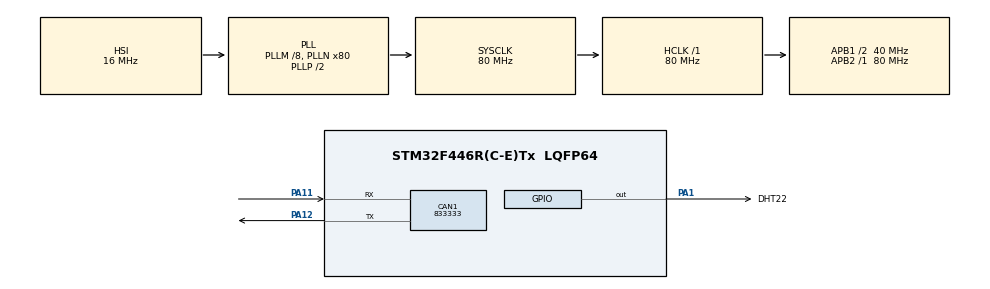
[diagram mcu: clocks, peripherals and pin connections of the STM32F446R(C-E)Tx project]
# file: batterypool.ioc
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CAN1.CalculateBaudRate=833333
CAN1.CalculateTimeBit=1200
CAN1.CalculateTimeQuantum=400.0
Mcu.Family=STM32F4
Mcu.Name=STM32F446R(C-E)Tx
Mcu.Package=LQFP64
NVIC.PriorityGroup=NVIC_PRIORITYGROUP_4
PA1.GPIO_Label=DHT22
PA1.GPIO_PuPd=GPIO_PULLUP
PA1.Signal=GPIO_Output
PA11.Mode=CAN_Activate
PA11.Signal=CAN1_RX
PA12.Mode=CAN_Activate
PA12.Signal=CAN1_TX
ProjectManager.HeapSize=0x200
ProjectManager.StackSize=0x400
ProjectManager.TargetToolchain=MDK-ARM V5.32
RCC.AHBFreq_Value=80000000
RCC.APB1CLKDivider=RCC_HCLK_DIV2
RCC.APB1Freq_Value=40000000
RCC.APB1TimFreq_Value=80000000
RCC.APB2Freq_Value=80000000
RCC.APB2TimFreq_Value=80000000
RCC.CortexFreq_Value=80000000
RCC.HCLKFreq_Value=80000000
RCC.PLLM=8
RCC.PLLN=80
RCC.SYSCLKFreq_VALUE=80000000
RCC.SYSCLKSource=RCC_SYSCLKSOURCE_PLLCLK
RCC.USBFreq_Value=80000000
RCC.VCOOutputFreq_Value=160000000
board=custom

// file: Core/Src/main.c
/* USER CODE BEGIN Header */
/**
  ******************************************************************************
  * @file           : main.c
  * @brief          : Main program body
  ******************************************************************************
  * @attention
  *
  * Copyright (c) 2023 STMicroelectronics.
  * All rights reserved.
  *
  * This software is licensed under terms that can be found in the LICENSE file
  * in the root directory of this software component.
  * If no LICENSE file comes with this software, it is provided AS-IS.
  *
  ******************************************************************************
  */
/* USER CODE END Header */
#include "main.h"
#include "can.h"
#include "gpio.h"

void SystemClock_Config(void);
/* USER CODE BEGIN PFP */
void CAN_Configuration(void);
void GPIO_Configuration(void);
void delay_ms(uint32_t ms);
/* USER CODE END PFP */

/* USER CODE BEGIN 0 */
uint8_t temperature = 0;

/* USER CODE END 0 */

int main(void)
{

  /* MCU Configuration--------------------------------------------------------*/

  /* Reset of all peripherals, Initializes the Flash interface and the Systick. */
  HAL_Init();

  /* Configure the system clock */
  SystemClock_Config();

  /* Initialize all configured peripherals */
  MX_GPIO_Init();
  MX_CAN1_Init();
  /* USER CODE BEGIN 2 */
	DHT22_Start();
	/* USER CODE END 2 */

  /* Infinite loop */
  /* USER CODE BEGIN WHILE */
  while (1)
  {
				temperature = DHT22_ReadTemperature();

    /* USER CODE END WHILE */

    /* USER CODE BEGIN 3 */
		// Send temperature over CAN bus
        CAN1->sTxMailBox[0].TDLR = temperature; // Assuming only 1 byte for temperature
        CAN1->sTxMailBox[0].TDTR = 1; // Set data length to 1 byte
        CAN1->sTxMailBox[0].TIR |= CAN_TI0R_TXRQ; // Set transmit request bit

        // Wait for transmission completion
        while ((CAN1->sTxMailBox[0].TIR & CAN_TI0R_TXRQ) != 0);

        delay_ms(1000); // Delay for 1 second before reading again
  }
  /* USER CODE END 3 */
}

void SystemClock_Config(void)
{
  RCC_OscInitTypeDef RCC_OscInitStruct = {0};
  RCC_ClkInitTypeDef RCC_ClkInitStruct = {0};

  /** Configure the main internal regulator output voltage
  */
  __HAL_RCC_PWR_CLK_ENABLE();
  __HAL_PWR_VOLTAGESCALING_CONFIG(PWR_REGULATOR_VOLTAGE_SCALE3);

  /** Initializes the RCC Oscillators according to the specified parameters
  * in the RCC_OscInitTypeDef structure.
  */
  RCC_OscInitStruct.OscillatorType = RCC_OSCILLATORTYPE_HSI;
  RCC_OscInitStruct.HSIState = RCC_HSI_ON;
  RCC_OscInitStruct.HSICalibrationValue = RCC_HSICALIBRATION_DEFAULT;
  RCC_OscInitStruct.PLL.PLLState = RCC_PLL_ON;
  RCC_OscInitStruct.PLL.PLLSource = RCC_PLLSOURCE_HSI;
  RCC_OscInitStruct.PLL.PLLM = 8;
  RCC_OscInitStruct.PLL.PLLN = 80;
  RCC_OscInitStruct.PLL.PLLP = RCC_PLLP_DIV2;
  RCC_OscInitStruct.PLL.PLLQ = 2;
  RCC_OscInitStruct.PLL.PLLR = 2;
  if (HAL_RCC_OscConfig(&RCC_OscInitStruct) != HAL_OK)
  {
    Error_Handler();
  }

  /** Initializes the CPU, AHB and APB buses clocks
  */
  RCC_ClkInitStruct.ClockType = RCC_CLOCKTYPE_HCLK|RCC_CLOCKTYPE_SYSCLK
                              |RCC_CLOCKTYPE_PCLK1|RCC_CLOCKTYPE_PCLK2;
  RCC_ClkInitStruct.SYSCLKSource = RCC_SYSCLKSOURCE_PLLCLK;
  RCC_ClkInitStruct.AHBCLKDivider = RCC_SYSCLK_DIV1;
  RCC_ClkInitStruct.APB1CLKDivider = RCC_HCLK_DIV2;
  RCC_ClkInitStruct.APB2CLKDivider = RCC_HCLK_DIV1;

  if (HAL_RCC_ClockConfig(&RCC_ClkInitStruct, FLASH_LATENCY_2) != HAL_OK)
  {
    Error_Handler();
  }
}

/* USER CODE BEGIN 4 */
void GPIO_Configuration(void) {
    // Configure GPIO pins for CAN peripheral
    RCC->AHB1ENR |= RCC_AHB1ENR_GPIOAEN; // Enable GPIOA clock

    // Configure GPIO pins for CAN1: PA11 (RX) and PA12 (TX)
    GPIOA->MODER |= GPIO_MODER_MODER11_1 | GPIO_MODER_MODER12_1; // Set pins to alternate function mode
    GPIOA->AFR[1] |= 0x440; // AF9 (CAN1) for pins 11 and 12
}

void CAN_Configuration(void) {
    // Enable CAN1 and GPIO clocks
    RCC->APB1ENR |= RCC_APB1ENR_CAN1EN;

    // Reset CAN1 peripheral
    CAN1->MCR |= CAN_MCR_RESET;
    while ((CAN1->MSR & CAN_MCR_RESET) != 0);

    // Exit sleep mode
    CAN1->MCR &= ~CAN_MCR_SLEEP;

    // Initialize CAN1
    CAN1->MCR |= CAN_MCR_INRQ; // Enter initialization mode
    while ((CAN1->MSR & CAN_MSR_INAK) != CAN_MSR_INAK);

    // Set CAN1 bit timings (assuming 125 kbps)
    CAN1->BTR = (5 << 20) | (4 << 16) | (12 << 0); // SJW=5, TS2=4, TS1=12, BRP=1 (125 kbps)

    // Leave initialization mode
    CAN1->MCR &= ~CAN_MCR_INRQ;
    while ((CAN1->MSR & CAN_MSR_INAK) == CAN_MSR_INAK);

    // Enable transmit mailbox 0 empty interrupt
    CAN1->IER |= CAN_IER_TMEIE;

    // Enable CAN1
    CAN1->MCR &= ~CAN_MCR_SLEEP;
    CAN1->MCR |= CAN_MCR_INRQ;
}

void delay_ms(uint32_t ms) {
    // Approximate delay in milliseconds
    // Adjust the following value based on your clock frequency and optimization level
    volatile uint32_t i;
    for (i = 0; i < (ms * 1000); i++) {}
}
/* USER CODE END 4 */

void Error_Handler(void)
{
  __disable_irq();
  while (1)
  {
  }
}
